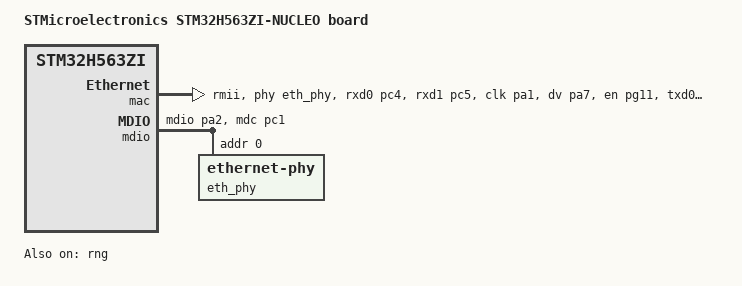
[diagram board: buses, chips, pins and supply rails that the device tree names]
/*
 * Copyright (c) 2021 Linaro Limited
 * Copyright (c) 2023 Thomas Stranger
 *
 * SPDX-License-Identifier: Apache-2.0
 */

/dts-v1/;
#include "nucleo_h563zi-common.dtsi"


/ {
	model = "STMicroelectronics STM32H563ZI-NUCLEO board";
	compatible = "st,stm32h563zi-nucleo";

	#address-cells = <1>;
	#size-cells = <1>;

	chosen {
		zephyr,console = &usart3;
		zephyr,shell-uart = &usart3;
		zephyr,sram = &sram1;
		zephyr,flash = &flash0;
		zephyr,code-partition = &slot0_partition;
		zephyr,canbus = &fdcan1;
	};

	aliases {
		led0 = &green_led_1;
		led1 = &yellow_led_1;
		sw0 = &user_button;
		watchdog0 = &iwdg;
		pwm-led0 = &pwm_led_1;
		volt-sensor0 = &vref;
		volt-sensor1 = &vbat;
	};
};

&rng {
	status = "okay";
};

&mac {
	status = "okay";
	pinctrl-0 = <&eth_rxd0_pc4
		     &eth_rxd1_pc5
		     &eth_ref_clk_pa1
		     &eth_crs_dv_pa7
		     &eth_tx_en_pg11
		     &eth_txd0_pg13
		     &eth_txd1_pb15>;
	pinctrl-names = "default";
	phy-connection-type = "rmii";
	phy-handle = <&eth_phy>;
};

&mdio {
	status = "okay";
	pinctrl-0 = <&eth_mdio_pa2 &eth_mdc_pc1>;
	pinctrl-names = "default";

	eth_phy: ethernet-phy@0 {
		compatible = "ethernet-phy";
		reg = <0x00>;
	};
};
